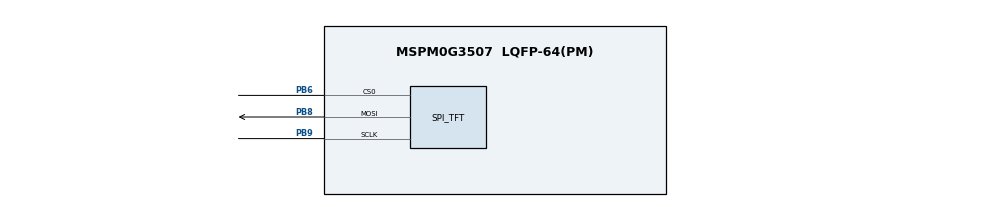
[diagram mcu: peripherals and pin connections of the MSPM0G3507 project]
/** example06: single ADC/DMA + ST7789 + 4x4 keypad. */
//@cliArgs --device "MSPM0G350X" --package "LQFP-64(PM)" --part "Default"
//@v2CliArgs --device "MSPM0G3507" --package "LQFP-64(PM)"
// @cliArgs --board /ti/boards/LP_MSPM0G3507 --rtos nortos
const ProjectConfig = scripting.addModule("/ti/project_config/ProjectConfig");
const Board = scripting.addModule("/ti/driverlib/Board");
const SYSCTL = scripting.addModule("/ti/driverlib/SYSCTL");
const ADC12 = scripting.addModule("/ti/driverlib/ADC12", {}, false);
const SIGNAL_ADC = ADC12.addInstance();
const TIMER = scripting.addModule("/ti/driverlib/TIMER", {}, false);
const SIGNAL_SAMPLE_TIMER = TIMER.addInstance();
const SPI = scripting.addModule("/ti/driverlib/SPI", {}, false);
const SPI_TFT = SPI.addInstance();
const GPIO = scripting.addModule("/ti/driverlib/GPIO", {}, false);
const TFT_GPIO = GPIO.addInstance();
const KEY_GPIO = GPIO.addInstance();
ProjectConfig.genLibCMSIS = true;
SIGNAL_ADC.$name = "SIGNAL_ADC";
SIGNAL_ADC.sampClkSrc = "DL_ADC12_CLOCK_ULPCLK";
SIGNAL_ADC.adcMem0chansel = "DL_ADC12_INPUT_CHAN_2";
SIGNAL_ADC.sampleTime0 = "62.5ns";
SIGNAL_ADC.powerDownMode = "DL_ADC12_POWER_DOWN_MODE_MANUAL";
SIGNAL_ADC.trigSrc = "DL_ADC12_TRIG_SRC_EVENT";
SIGNAL_ADC.repeatMode = true;
SIGNAL_ADC.adcMem0trig = "DL_ADC12_TRIGGER_MODE_TRIGGER_NEXT";
SIGNAL_ADC.subChanID = 1;
SIGNAL_ADC.configureDMA = true;
SIGNAL_ADC.sampCnt = 1;
SIGNAL_ADC.enabledDMATriggers = ["DL_ADC12_DMA_MEM0_RESULT_LOADED"];
SIGNAL_ADC.enabledInterrupts = ["DL_ADC12_INTERRUPT_DMA_DONE"];
SIGNAL_ADC.peripheral.$assign = "ADC0";
SIGNAL_ADC.peripheral.adcPin2.$assign = "PA25";
SIGNAL_ADC.DMA_CHANNEL.$name = "SIGNAL_ADC_DMA";
SIGNAL_ADC.DMA_CHANNEL.peripheral.$assign = "DMA_CH0";
SIGNAL_ADC.DMA_CHANNEL.addressMode = "f2b";
SIGNAL_ADC.DMA_CHANNEL.srcLength = "HALF_WORD";
SIGNAL_ADC.DMA_CHANNEL.dstLength = "HALF_WORD";
SIGNAL_ADC.DMA_CHANNEL.transferMode = "SINGLE";
SIGNAL_SAMPLE_TIMER.$name = "SIGNAL_SAMPLE_TIMER";
SIGNAL_SAMPLE_TIMER.timerClkSrc = "BUSCLK";
SIGNAL_SAMPLE_TIMER.timerClkDiv = 1;
SIGNAL_SAMPLE_TIMER.timerClkPrescale = 1;
SIGNAL_SAMPLE_TIMER.timerPeriod = "2us";
SIGNAL_SAMPLE_TIMER.timerMode = "PERIODIC";
SIGNAL_SAMPLE_TIMER.event1PublisherChannel = 1;
SIGNAL_SAMPLE_TIMER.event1ControllerInterruptEn = ["ZERO_EVENT"];
SIGNAL_SAMPLE_TIMER.peripheral.$assign = "TIMG0";
SPI_TFT.$name = "SPI_TFT";
SPI_TFT.peripheral.$assign = "SPI1";
SPI_TFT.peripheral.sclkPin.$assign = "PB9";
SPI_TFT.peripheral.mosiPin.$assign = "PB8";
SPI_TFT.peripheral.cs0Pin.$assign = "PB6";
TFT_GPIO.$name = "GPIO_TFT_CTRL";
TFT_GPIO.associatedPins.create(2);
TFT_GPIO.associatedPins[0].$name = "TFT_DC";
TFT_GPIO.associatedPins[0].assignedPort = "PORTB";
TFT_GPIO.associatedPins[0].assignedPin = "15";
TFT_GPIO.associatedPins[1].$name = "TFT_BLK";
TFT_GPIO.associatedPins[1].initialValue = "SET";
TFT_GPIO.associatedPins[1].assignedPort = "PORTB";
TFT_GPIO.associatedPins[1].assignedPin = "12";
KEY_GPIO.$name = "GPIO_KEYPAD";
KEY_GPIO.associatedPins.create(8);
KEY_GPIO.associatedPins[0].$name = "KEYPAD_R1";
KEY_GPIO.associatedPins[0].assignedPort = "PORTB";
KEY_GPIO.associatedPins[0].assignedPin = "16";
KEY_GPIO.associatedPins[0].direction = "OUTPUT";
KEY_GPIO.associatedPins[0].initialValue = "SET";
KEY_GPIO.associatedPins[1].$name = "KEYPAD_R2";
KEY_GPIO.associatedPins[1].assignedPort = "PORTB";
KEY_GPIO.associatedPins[1].assignedPin = "0";
KEY_GPIO.associatedPins[1].direction = "OUTPUT";
KEY_GPIO.associatedPins[1].initialValue = "SET";
KEY_GPIO.associatedPins[2].$name = "KEYPAD_R3";
KEY_GPIO.associatedPins[2].assignedPort = "PORTB";
KEY_GPIO.associatedPins[2].assignedPin = "7";
KEY_GPIO.associatedPins[2].direction = "OUTPUT";
KEY_GPIO.associatedPins[2].initialValue = "SET";
KEY_GPIO.associatedPins[3].$name = "KEYPAD_R4";
KEY_GPIO.associatedPins[3].assignedPort = "PORTB";
KEY_GPIO.associatedPins[3].assignedPin = "17";
KEY_GPIO.associatedPins[3].direction = "OUTPUT";
KEY_GPIO.associatedPins[3].initialValue = "SET";
KEY_GPIO.associatedPins[4].$name = "KEYPAD_C1";
KEY_GPIO.associatedPins[4].assignedPort = "PORTB";
KEY_GPIO.associatedPins[4].assignedPin = "18";
KEY_GPIO.associatedPins[4].direction = "INPUT";
KEY_GPIO.associatedPins[4].internalResistor = "PULL_UP";
KEY_GPIO.associatedPins[5].$name = "KEYPAD_C2";
KEY_GPIO.associatedPins[5].assignedPort = "PORTB";
KEY_GPIO.associatedPins[5].assignedPin = "13";
KEY_GPIO.associatedPins[5].direction = "INPUT";
KEY_GPIO.associatedPins[5].internalResistor = "PULL_UP";
KEY_GPIO.associatedPins[6].$name = "KEYPAD_C3";
KEY_GPIO.associatedPins[6].assignedPort = "PORTB";
KEY_GPIO.associatedPins[6].assignedPin = "20";
KEY_GPIO.associatedPins[6].direction = "INPUT";
KEY_GPIO.associatedPins[6].internalResistor = "PULL_UP";
KEY_GPIO.associatedPins[7].$name = "KEYPAD_C4";
KEY_GPIO.associatedPins[7].assignedPort = "PORTB";
KEY_GPIO.associatedPins[7].assignedPin = "4";
KEY_GPIO.associatedPins[7].direction = "INPUT";
KEY_GPIO.associatedPins[7].internalResistor = "PULL_UP";
SYSCTL.forceDefaultClkConfig = true;
SYSCTL.clockTreeEn = true;
